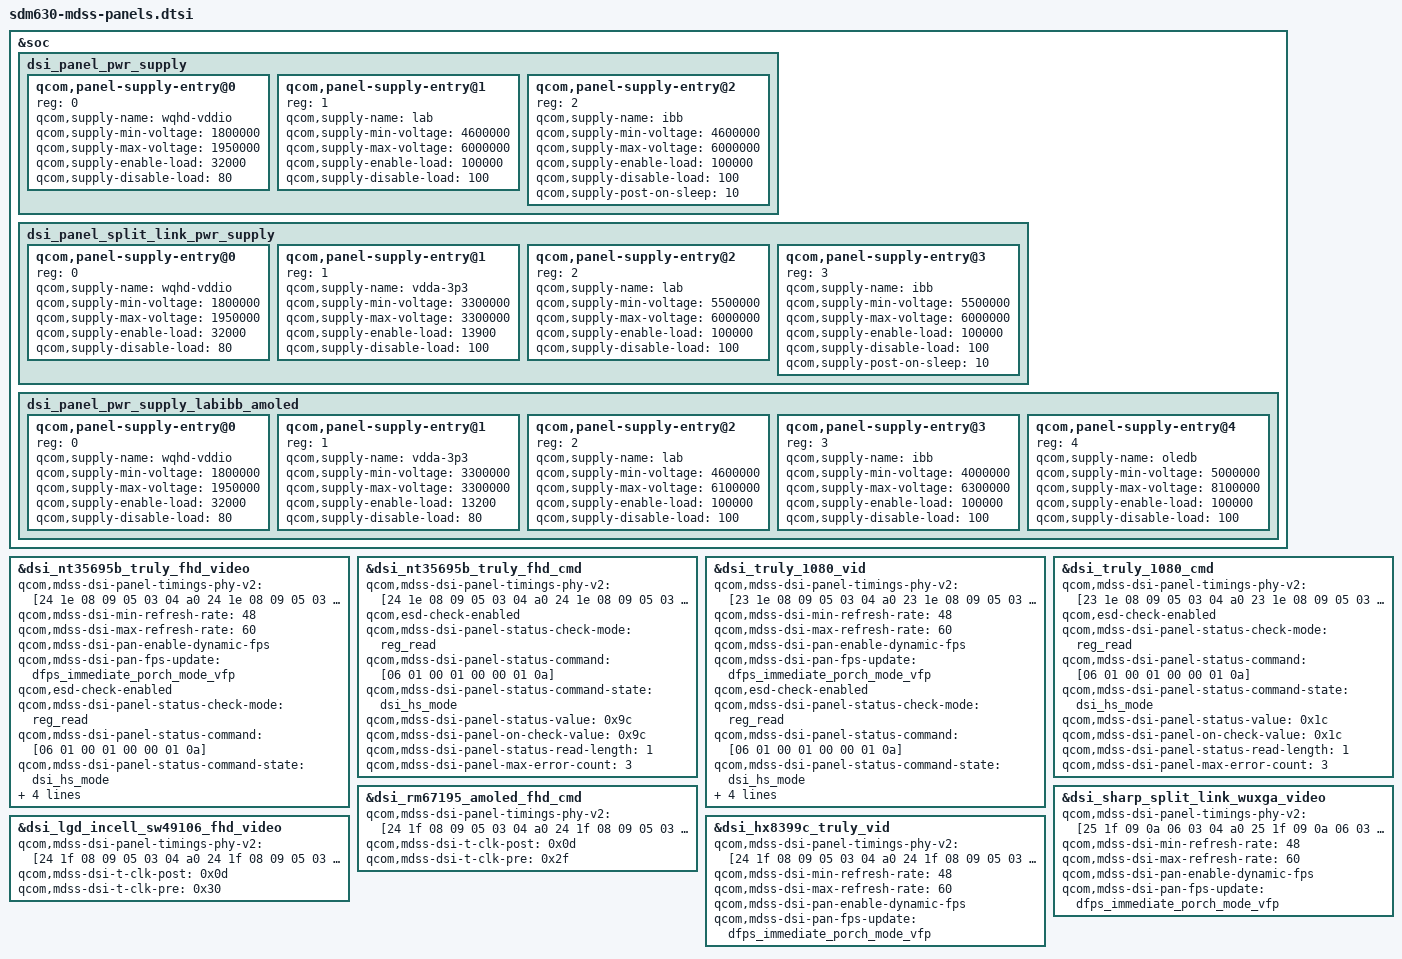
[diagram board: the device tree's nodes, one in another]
/* Copyright (c) 2017-2018, The Linux Foundation. All rights reserved.
 *
 * This program is free software; you can redistribute it and/or modify
 * it under the terms of the GNU General Public License version 2 and
 * only version 2 as published by the Free Software Foundation.
 *
 * This program is distributed in the hope that it will be useful,
 * but WITHOUT ANY WARRANTY; without even the implied warranty of
 * MERCHANTABILITY or FITNESS FOR A PARTICULAR PURPOSE.  See the
 * GNU General Public License for more details.
 */

#include "dsi-panel-sim-video.dtsi"
#include "dsi-panel-nt35695b-truly-fhd-video.dtsi"
#include "dsi-panel-nt35695b-truly-fhd-cmd.dtsi"
#include "dsi-panel-truly-1080p-cmd.dtsi"
#include "dsi-panel-truly-1080p-video.dtsi"
#include "dsi-panel-rm67195-amoled-fhd-cmd.dtsi"
#include "dsi-panel-sharp-split-link-wuxga-video.dtsi"
#include "dsi-panel-lgd-incell-sw49106-fhd-video.dtsi"
#include "dsi-panel-hx8399c-fhd-plus-video.dtsi"

&soc {
	dsi_panel_pwr_supply: dsi_panel_pwr_supply {
		#address-cells = <1>;
		#size-cells = <0>;

		qcom,panel-supply-entry@0 {
			reg = <0>;
			qcom,supply-name = "wqhd-vddio";
			qcom,supply-min-voltage = <1800000>;
			qcom,supply-max-voltage = <1950000>;
			qcom,supply-enable-load = <32000>;
			qcom,supply-disable-load = <80>;
		};

		qcom,panel-supply-entry@1 {
			reg = <1>;
			qcom,supply-name = "lab";
			qcom,supply-min-voltage = <4600000>;
			qcom,supply-max-voltage = <6000000>;
			qcom,supply-enable-load = <100000>;
			qcom,supply-disable-load = <100>;
		};

		qcom,panel-supply-entry@2 {
			reg = <2>;
			qcom,supply-name = "ibb";
			qcom,supply-min-voltage = <4600000>;
			qcom,supply-max-voltage = <6000000>;
			qcom,supply-enable-load = <100000>;
			qcom,supply-disable-load = <100>;
			qcom,supply-post-on-sleep = <10>;
		};
	};

	dsi_panel_split_link_pwr_supply: dsi_panel_split_link_pwr_supply {
		#address-cells = <1>;
		#size-cells = <0>;

		qcom,panel-supply-entry@0 {
			reg = <0>;
			qcom,supply-name = "wqhd-vddio";
			qcom,supply-min-voltage = <1800000>;
			qcom,supply-max-voltage = <1950000>;
			qcom,supply-enable-load = <32000>;
			qcom,supply-disable-load = <80>;
		};

		qcom,panel-supply-entry@1 {
			reg = <1>;
			qcom,supply-name = "vdda-3p3";
			qcom,supply-min-voltage = <3300000>;
			qcom,supply-max-voltage = <3300000>;
			qcom,supply-enable-load = <13900>;
			qcom,supply-disable-load = <100>;
		};

		qcom,panel-supply-entry@2 {
			reg = <2>;
			qcom,supply-name = "lab";
			qcom,supply-min-voltage = <5500000>;
			qcom,supply-max-voltage = <6000000>;
			qcom,supply-enable-load = <100000>;
			qcom,supply-disable-load = <100>;
		};

		qcom,panel-supply-entry@3 {
			reg = <3>;
			qcom,supply-name = "ibb";
			qcom,supply-min-voltage = <5500000>;
			qcom,supply-max-voltage = <6000000>;
			qcom,supply-enable-load = <100000>;
			qcom,supply-disable-load = <100>;
			qcom,supply-post-on-sleep = <10>;
		};
	};

	dsi_panel_pwr_supply_labibb_amoled:
			dsi_panel_pwr_supply_labibb_amoled {
		#address-cells = <1>;
		#size-cells = <0>;

		qcom,panel-supply-entry@0 {
			reg = <0>;
			qcom,supply-name = "wqhd-vddio";
			qcom,supply-min-voltage = <1800000>;
			qcom,supply-max-voltage = <1950000>;
			qcom,supply-enable-load = <32000>;
			qcom,supply-disable-load = <80>;
		};

		qcom,panel-supply-entry@1 {
			reg = <1>;
			qcom,supply-name = "vdda-3p3";
			qcom,supply-min-voltage = <3300000>;
			qcom,supply-max-voltage = <3300000>;
			qcom,supply-enable-load = <13200>;
			qcom,supply-disable-load = <80>;
		};

		qcom,panel-supply-entry@2 {
			reg = <2>;
			qcom,supply-name = "lab";
			qcom,supply-min-voltage = <4600000>;
			qcom,supply-max-voltage = <6100000>;
			qcom,supply-enable-load = <100000>;
			qcom,supply-disable-load = <100>;
		};

		qcom,panel-supply-entry@3 {
			reg = <3>;
			qcom,supply-name = "ibb";
			qcom,supply-min-voltage = <4000000>;
			qcom,supply-max-voltage = <6300000>;
			qcom,supply-enable-load = <100000>;
			qcom,supply-disable-load = <100>;
		};

		qcom,panel-supply-entry@4 {
			reg = <4>;
			qcom,supply-name = "oledb";
			qcom,supply-min-voltage = <5000000>;
			qcom,supply-max-voltage = <8100000>;
			qcom,supply-enable-load = <100000>;
			qcom,supply-disable-load = <100>;
		};
	};
};

&dsi_nt35695b_truly_fhd_video {
	qcom,mdss-dsi-panel-timings-phy-v2 = [24 1e 08 09 05 03 04 a0
		24 1e 08 09 05 03 04 a0
		24 1e 08 09 05 03 04 a0
		24 1e 08 09 05 03 04 a0
		24 1a 08 09 05 03 04 a0];
	qcom,mdss-dsi-min-refresh-rate = <48>;
	qcom,mdss-dsi-max-refresh-rate = <60>;
	qcom,mdss-dsi-pan-enable-dynamic-fps;
	qcom,mdss-dsi-pan-fps-update = "dfps_immediate_porch_mode_vfp";
	qcom,esd-check-enabled;
	qcom,mdss-dsi-panel-status-check-mode = "reg_read";
	qcom,mdss-dsi-panel-status-command = [06 01 00 01 00 00 01 0a];
	qcom,mdss-dsi-panel-status-command-state = "dsi_hs_mode";
	qcom,mdss-dsi-panel-status-value = <0x9c>;
	qcom,mdss-dsi-panel-on-check-value = <0x9c>;
	qcom,mdss-dsi-panel-status-read-length = <1>;
	qcom,mdss-dsi-panel-max-error-count = <3>;

};

&dsi_nt35695b_truly_fhd_cmd {
	qcom,mdss-dsi-panel-timings-phy-v2 = [24 1e 08 09 05 03 04 a0
		24 1e 08 09 05 03 04 a0
		24 1e 08 09 05 03 04 a0
		24 1e 08 09 05 03 04 a0
		24 1a 08 09 05 03 04 a0];
	qcom,esd-check-enabled;
	qcom,mdss-dsi-panel-status-check-mode = "reg_read";
	qcom,mdss-dsi-panel-status-command = [06 01 00 01 00 00 01 0a];
	qcom,mdss-dsi-panel-status-command-state = "dsi_hs_mode";
	qcom,mdss-dsi-panel-status-value = <0x9c>;
	qcom,mdss-dsi-panel-on-check-value = <0x9c>;
	qcom,mdss-dsi-panel-status-read-length = <1>;
	qcom,mdss-dsi-panel-max-error-count = <3>;

};

&dsi_truly_1080_vid {
	qcom,mdss-dsi-panel-timings-phy-v2 = [23 1e 08 09 05 03 04 a0
		23 1e 08 09 05 03 04 a0
		23 1e 08 09 05 03 04 a0
		23 1e 08 09 05 03 04 a0
		23 1a 08 09 05 03 04 a0];
	qcom,mdss-dsi-min-refresh-rate = <48>;
	qcom,mdss-dsi-max-refresh-rate = <60>;
	qcom,mdss-dsi-pan-enable-dynamic-fps;
	qcom,mdss-dsi-pan-fps-update = "dfps_immediate_porch_mode_vfp";
	qcom,esd-check-enabled;
	qcom,mdss-dsi-panel-status-check-mode = "reg_read";
	qcom,mdss-dsi-panel-status-command = [06 01 00 01 00 00 01 0a];
	qcom,mdss-dsi-panel-status-command-state = "dsi_hs_mode";
	qcom,mdss-dsi-panel-status-value = <0x1c>;
	qcom,mdss-dsi-panel-on-check-value = <0x1c>;
	qcom,mdss-dsi-panel-status-read-length = <1>;
	qcom,mdss-dsi-panel-max-error-count = <3>;

};

&dsi_truly_1080_cmd {
	qcom,mdss-dsi-panel-timings-phy-v2 = [23 1e 08 09 05 03 04 a0
		23 1e 08 09 05 03 04 a0
		23 1e 08 09 05 03 04 a0
		23 1e 08 09 05 03 04 a0
		23 1a 08 09 05 03 04 a0];
	qcom,esd-check-enabled;
	qcom,mdss-dsi-panel-status-check-mode = "reg_read";
	qcom,mdss-dsi-panel-status-command = [06 01 00 01 00 00 01 0a];
	qcom,mdss-dsi-panel-status-command-state = "dsi_hs_mode";
	qcom,mdss-dsi-panel-status-value = <0x1c>;
	qcom,mdss-dsi-panel-on-check-value = <0x1c>;
	qcom,mdss-dsi-panel-status-read-length = <1>;
	qcom,mdss-dsi-panel-max-error-count = <3>;

};

&dsi_rm67195_amoled_fhd_cmd {
	qcom,mdss-dsi-panel-timings-phy-v2 = [24 1f 08 09 05 03 04 a0
		24 1f 08 09 05 03 04 a0
		24 1f 08 09 05 03 04 a0
		24 1f 08 09 05 03 04 a0
		24 1a 08 09 05 03 04 a0];
	qcom,mdss-dsi-t-clk-post = <0x0d>;
	qcom,mdss-dsi-t-clk-pre = <0x2f>;
};

&dsi_sharp_split_link_wuxga_video {
	qcom,mdss-dsi-panel-timings-phy-v2 = [25 1f 09 0a 06 03 04 a0
		25 1f 09 0a 06 03 04 a0
		25 1f 09 0a 06 03 04 a0
		25 1f 09 0a 06 03 04 a0
		25 1f 08 0a 06 03 04 a0];
	qcom,mdss-dsi-min-refresh-rate = <48>;
	qcom,mdss-dsi-max-refresh-rate = <60>;
	qcom,mdss-dsi-pan-enable-dynamic-fps;
	qcom,mdss-dsi-pan-fps-update = "dfps_immediate_porch_mode_vfp";
};

&dsi_lgd_incell_sw49106_fhd_video {
	qcom,mdss-dsi-panel-timings-phy-v2 = [24 1f 08 09 05 03 04 a0
		24 1f 08 09 05 03 04 a0
		24 1f 08 09 05 03 04 a0
		24 1f 08 09 05 03 04 a0
		24 1b 08 09 05 03 04 a0];
	qcom,mdss-dsi-t-clk-post = <0x0d>;
	qcom,mdss-dsi-t-clk-pre = <0x30>;
};

&dsi_hx8399c_truly_vid {
	qcom,mdss-dsi-panel-timings-phy-v2 = [24 1f 08 09 05 03 04 a0
		24 1f 08 09 05 03 04 a0
		24 1f 08 09 05 03 04 a0
		24 1f 08 09 05 03 04 a0
		24 1c 08 09 05 03 04 a0];
	qcom,mdss-dsi-min-refresh-rate = <48>;
	qcom,mdss-dsi-max-refresh-rate = <60>;
	qcom,mdss-dsi-pan-enable-dynamic-fps;
	qcom,mdss-dsi-pan-fps-update = "dfps_immediate_porch_mode_vfp";
};
